AUTOSAR XML (schema 4-0-3)
package /MICROSAR_SWCS_DEV/BswM_swc/ComponentTypes
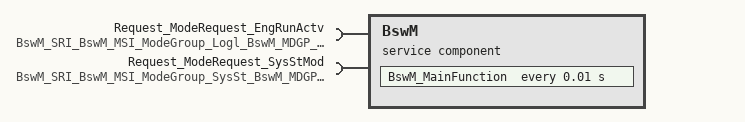
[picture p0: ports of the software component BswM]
  service sw component type BswM
    require port Request_ModeRequest_EngRunActv: nonqueued-receiver-com-spec{data-element=requestedMode, filter=data-filter-type=ALWAYS, init-value=FALSE}, required-interface=BswM_SRI_BswM_MSI_ModeGroup_Logl_BswM_MDGP_ModeGroup_Logl
    require port Request_ModeRequest_SysStMod: nonqueued-receiver-com-spec{data-element=requestedMode, filter=data-filter-type=ALWAYS, init-value=DISABLE}, required-interface=BswM_SRI_BswM_MSI_ModeGroup_SysSt_BswM_MDGP_ModeGroup_SysSt
    behavior BswMInternalBehavior: included-data-type-set=data-type=[BswM_ModeGroup_Logl, BswM_ModeGroup_SysSt]
      timing event Timer_BswM_MainFunction: start-on-event=BswM_MainFunction, period=0.01
      port-api-options:
        enable-take-address=true, indirect-api=false, port=Request_ModeRequest_EngRunActv
        enable-take-address=true, indirect-api=false, port=Request_ModeRequest_SysStMod
      runnable BswM_MainFunction
        data-receive-point-by-arguments:
          access DataReceivePointBswM_MainFunction_Request_ModeRequest_EngRunActv_requestedMode: accessed-variable=Request_ModeRequest_EngRunActv.requestedMode
          access DataReceivePointBswM_MainFunction_Request_ModeRequest_SysStMod_requestedMode: accessed-variable=Request_ModeRequest_SysStMod.requestedMode
  swc implementation BswMImplementation: behavior=BswMInternalBehavior
    code-descriptors:
      code Default: artifact-descriptors=autosar-engineering-object={short-label=Default, category=SWSRC}
